VERSION ""

NS_ :

BS_:

BU_: XXX

BO_ 258 STEERING: 8 XXX
 SG_ STEER_ANGLE : 7|16@0+ (0.3187251,-1307.888) [-360|360] "deg" XXX
 SG_ STEERING_RATE : 23|16@0+ (1,-4096) [0|8191] "" XXX

BO_ 653 BRAKE_MODULE: 2 XXX
 SG_ BRAKE_PRESSURE : 15|8@0+ (1,0) [0|255] "" XXX
 SG_ BRAKE_PRESSED : 4|1@0+ (1,0) [0|4] "" XXX

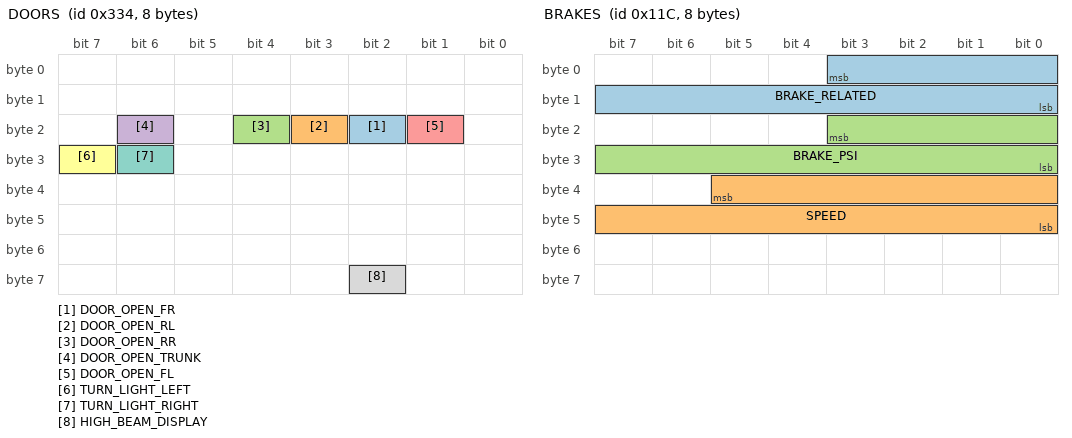
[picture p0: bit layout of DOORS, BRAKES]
BO_ 820 DOORS: 8 XXX
 SG_ DOOR_OPEN_FR : 18|1@0+ (1,0) [0|1] "" XXX
 SG_ DOOR_OPEN_RL : 19|1@0+ (1,0) [0|1] "" XXX
 SG_ DOOR_OPEN_RR : 20|1@0+ (1,0) [0|1] "" XXX
 SG_ DOOR_OPEN_TRUNK : 22|1@0+ (1,0) [0|1] "" XXX
 SG_ DOOR_OPEN_FL : 17|1@0+ (1,0) [0|1] "" XXX
 SG_ TURN_LIGHT_LEFT : 31|1@0+ (1,0) [0|1] "" XXX
 SG_ TURN_LIGHT_RIGHT : 30|1@0+ (1,0) [0|1] "" XXX
 SG_ HIGH_BEAM_DISPLAY : 58|1@1+ (1,0) [0|1] "" XXX

BO_ 284 BRAKES: 8 XXX
 SG_ BRAKE_RELATED : 3|12@0+ (1,0) [0|255] "" XXX
 SG_ SPEED : 37|14@0+ (1,0) [0|255] "" XXX
 SG_ BRAKE_PSI : 19|12@0+ (1,0) [0|4095] "" XXX

BO_ 320 NEW_MSG_2: 8 XXX
 SG_ SPEED_RELATED : 47|8@0+ (1,0) [0|63] "" XXX
 SG_ BRAKE_PRESSED : 2|3@0+ (1,0) [0|7] "" XXX

BO_ 736 TRIP: 8 XXX
 SG_ DISTANCE_COUNTER : 7|16@0+ (0,0) [0|65535] "Meters" XXX
 SG_ DISTANCE_COUNTER_2 : 23|16@0+ (1,0) [0|65535] "Meters" XXX

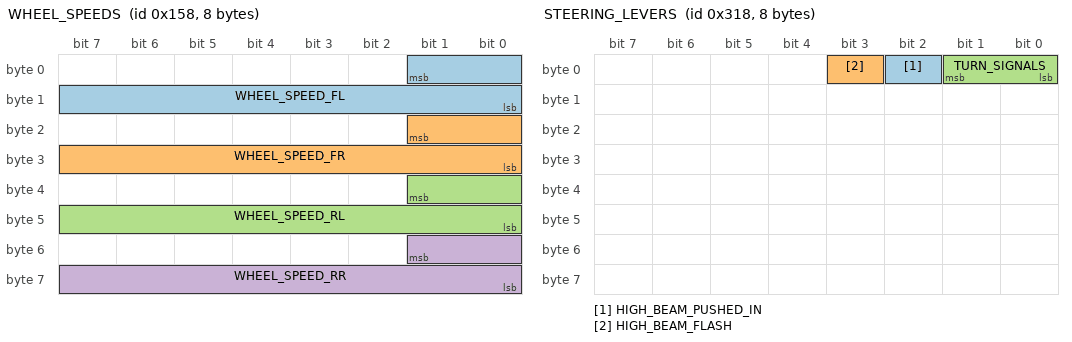
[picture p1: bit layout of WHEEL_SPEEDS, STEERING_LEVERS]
BO_ 344 WHEEL_SPEEDS: 8 XXX
 SG_ WHEEL_SPEED_FL : 1|10@0+ (1,0) [0|65535] "" XXX
 SG_ WHEEL_SPEED_FR : 17|10@0+ (1,0) [0|255] "" XXX
 SG_ WHEEL_SPEED_RL : 33|10@0+ (1,0) [0|3] "" XXX
 SG_ WHEEL_SPEED_RR : 49|10@0+ (1,0) [0|255] "" XXX

BO_ 792 STEERING_LEVERS: 8 XXX
 SG_ HIGH_BEAM_PUSHED_IN : 2|1@1+ (1,0) [0|3] "" XXX
 SG_ HIGH_BEAM_FLASH : 3|1@1+ (1,0) [0|3] "" XXX
 SG_ TURN_SIGNALS : 1|2@0+ (1,0) [0|3] "" XXX

BO_ 264 ACCEL_PEDAL_MSG: 8 XXX
 SG_ ACCEL_PEDAL : 35|12@0+ (1,-3734) [0|4095] "1" XXX

BO_ 680 GEAR: 8 XXX
 SG_ PRNDL : 23|4@0+ (1,0) [0|15] "" XXX

BO_ 520 BRAKES: 8 XXX
 SG_ HUMAN_BRAKE : 19|4@0+ (1,0) [0|15] "" XXX

BO_ 571 STEERING_WHEEL_BUTTONS_RIGHT: 8 XXX
 SG_ STEERING_WHEEL_BUTTONS_RIGHT : 7|8@0+ (1,0) [0|15] "" XXX

BO_ 559 GAS_PEDAL_HUMAN: 8 XXX
 SG_ GASPEDAL_HUMAN : 7|8@0+ (1,0) [0|255] "" XXX

BO_ 729 FRONT_CAM: 8 XXX
 SG_ FRONT_CAM : 23|8@0+ (1,0) [0|255] "" XXX

BO_ 280 ENGINE: 8 XXX
 SG_ RPM : 3|12@0+ (1,0) [0|4095] "" XXX
 SG_ TORQUE_REQUEST_MAYBE : 19|12@0+ (1,0) [0|4095] "" XXX

CM_ SG_ 258 STEER_ANGLE "positive is left (counter-clockwise), 0x1000=0 degrees, 0x14d5 max left, 0x0b23 max right";
CM_ SG_ 653 BRAKE_PRESSURE "max seems to be 148";
CM_ SG_ 820 TURN_LIGHT_LEFT "oscillates with the light blinking";
CM_ SG_ 820 TURN_LIGHT_RIGHT "hazard blinks both right and left lights";
CM_ SG_ 284 BRAKE_RELATED "Correlates with braking";
CM_ SG_ 284 SPEED "Another Speed Signal, Maybe RPMs?";
CM_ SG_ 320 BRAKE_PRESSED "Value is 5 when brake is pressed";
CM_ SG_ 792 HIGH_BEAM_FLASH "use this for genericToggle";
CM_ SG_ 792 TURN_SIGNALS "1=Left, 2=Right, 8=FlashtoPass, 4=autohighbeam";
CM_ SG_ 264 ACCEL_PEDAL "0x7dc=0%, 0xf9c=100%, not in ACC so seems to be actual pedal. Use for gasPressed";
CM_ SG_ 680 PRNDL "e=reverse, c=park, d=neutral, 1=drive, 2=drive, 3=drive, 4=drive, 5=drive, 6=drive, 7=drive, 8=drive";
CM_ SG_ 520 HUMAN_BRAKE "0=not pressed, 4=pressed, could be brake lights";
CM_ SG_ 571 STEERING_WHEEL_BUTTONS_RIGHT "0x04=SET+, 0x08=SET-, 0x01=CANCEL, 0x40=REGCRUISE, 0x10=RES, 0x80=ACC, 0x02=DecreaseFollow, IncreaseFollow not shown";
CM_ SG_ 559 GASPEDAL_HUMAN "Me pressing the gas";
CM_ SG_ 729 FRONT_CAM "0x08, 0x0c, 0x04";
CM_ SG_ 280 RPM "0xdfa is approx 7-800 rpm 0xfab is 0 rpm (not running) ";
CM_ SG_ 280 TORQUE_REQUEST_MAYBE "0x7db is 0% or zero request, 0x96c is not running";
VAL_ 792 TURN_SIGNALS 2 "Right" 1 "Left" ;
VAL_ 680 PRNDL 8 "Drive" 7 "Drive" 6 "Drive" 5 "Drive" 4 "Drive" 3 "Drive" 2 "Drive" 1 "Drive" D "Neutral" E "Reverse" C "Park" ;
